# MAIN_PADCFG_CTRL_MAIN_PADCFG_CTRL_MMR_CFG0_000F0000h register map
Vendor: Texas Instruments
Peripheral module from a debugger description file (folder am62D).
Registers are 32-bit, access per field, reset 0x8214007 unless marked. A register's access mark holds for its fields unless they carry their own. Offsets are as the file gives them; lines under a group give offsets from that group; [hi:lo] are bit positions; {n}, {i} and the like mark numbered series; 'fields as' and 'values as' point back to an identical list; <NAME> marks a mode.

## main_padcfg_ctrl_mmr_cfg0 (part 1 of 3)
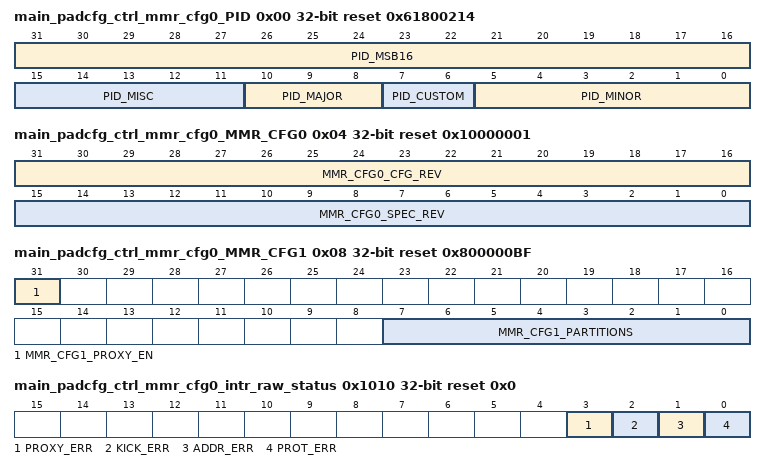
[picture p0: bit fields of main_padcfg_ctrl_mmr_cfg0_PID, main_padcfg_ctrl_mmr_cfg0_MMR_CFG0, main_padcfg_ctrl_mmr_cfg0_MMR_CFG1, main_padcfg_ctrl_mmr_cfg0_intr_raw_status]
0x00 main_padcfg_ctrl_mmr_cfg0_PID ro reset 0x61800214
  [31:16] PID_MSB16 — Reset Source: mod_g_rst_n
  [15:11] PID_MISC — Reset Source: mod_g_rst_n
  [10:8] PID_MAJOR — Reset Source: mod_g_rst_n
  [7:6] PID_CUSTOM — Reset Source: mod_g_rst_n
  [5:0] PID_MINOR — Reset Source: mod_g_rst_n
0x04 main_padcfg_ctrl_mmr_cfg0_MMR_CFG0 ro reset 0x10000001
  [31:16] MMR_CFG0_CFG_REV — Major configuration release Reset Source: mod_por_rst_n
  [15:0] MMR_CFG0_SPEC_REV — Minor spec-only revision. Doesn't change RTL release Reset Source: mod_por_rst_n
0x08 main_padcfg_ctrl_mmr_cfg0_MMR_CFG1 ro reset 0x800000BF
  [31] MMR_CFG1_PROXY_EN — Proxy addressing enabled Reset Source: mod_por_rst_n
  [7:0] MMR_CFG1_PARTITIONS — Indicates present partitions Reset Source: mod_por_rst_n
0x1008 main_padcfg_ctrl_mmr_cfg0_LOCK0_KICK0 rw reset 0x0
  [31:0] LOCK0_KICK0 — - KICK0 component Reset Source: mod_g_rst_n
0x100C main_padcfg_ctrl_mmr_cfg0_LOCK0_KICK1 rw reset 0x0
  [31:0] LOCK0_KICK1 — - KICK1 component Reset Source: mod_g_rst_n
0x1010 main_padcfg_ctrl_mmr_cfg0_intr_raw_status access not given reset 0x0
  [3] PROXY_ERR — Proxy0 access violation error. Raw status is read. Write a 1 to set the status. Writing a 0 has no effect. Reset Source: mod_g_rst_n (access R/W1TS)
  [2] KICK_ERR — Kick access violation error. Raw status is read. Write a 1 to set the status. Writing a 0 has no effect. Reset Source: mod_g_rst_n (access R/W1TS)
  [1] ADDR_ERR — Addressing violation error. Raw status is read. Write a 1 to set the status. Writing a 0 has no effect. Reset Source: mod_g_rst_n (access R/W1TS)
  [0] PROT_ERR — Protection violation error. Raw status is read. Write a 1 to set the status. Writing a 0 has no effect. Reset Source: mod_g_rst_n (access R/W1TS)
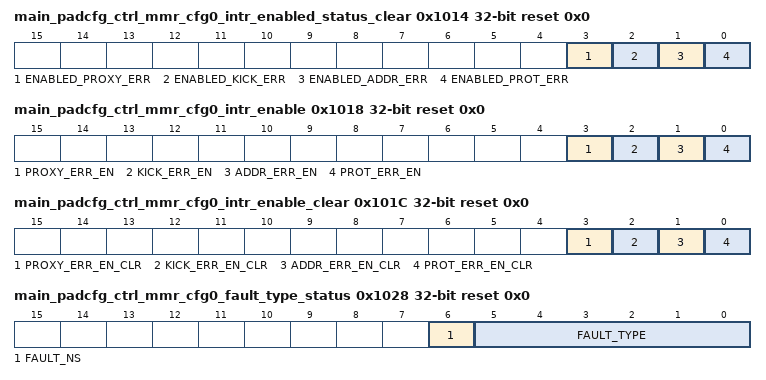
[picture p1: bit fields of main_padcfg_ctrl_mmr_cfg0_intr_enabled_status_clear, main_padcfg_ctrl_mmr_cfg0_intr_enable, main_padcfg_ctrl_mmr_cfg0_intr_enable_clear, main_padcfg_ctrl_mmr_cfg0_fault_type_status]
0x1014 main_padcfg_ctrl_mmr_cfg0_intr_enabled_status_clear access not given reset 0x0
  [3] ENABLED_PROXY_ERR — Proxy0 access violation error. Enabled status is read. Write a 1 to clear the status. Writing a 0 has no effect. Reset Source: mod_g_rst_n (access R/W1TC)
  [2] ENABLED_KICK_ERR — Kick access violation error. Enabled status is read. Write a 1 to clear the status. Writing a 0 has no effect. Reset Source: mod_g_rst_n (access R/W1TC)
  [1] ENABLED_ADDR_ERR — Addressing violation error. Enabled status is read. Write a 1 to clear the status. Writing a 0 has no effect. Reset Source: mod_g_rst_n (access R/W1TC)
  [0] ENABLED_PROT_ERR — Protection violation error. Enabled status is read. Write a 1 to clear the status. Writing a 0 has no effect. Reset Source: mod_g_rst_n (access R/W1TC)
0x1018 main_padcfg_ctrl_mmr_cfg0_intr_enable access not given reset 0x0
  [3] PROXY_ERR_EN — Proxy0 access violation error enable. Write a 1 to set the enable. Writing a 0 has no effect. Reset Source: mod_g_rst_n (access R/W1TS)
  [2] KICK_ERR_EN — Kick access violation error enable. Write a 1 to set the enable. Writing a 0 has no effect. Reset Source: mod_g_rst_n (access R/W1TS)
  [1] ADDR_ERR_EN — Addressing violation error enable. Write a 1 to set the enable. Writing a 0 has no effect. Reset Source: mod_g_rst_n (access R/W1TS)
  [0] PROT_ERR_EN — Protection violation error enable. Write a 1 to set the enable. Writing a 0 has no effect. Reset Source: mod_g_rst_n (access R/W1TS)
0x101C main_padcfg_ctrl_mmr_cfg0_intr_enable_clear access not given reset 0x0
  [3] PROXY_ERR_EN_CLR — Proxy0 access violation error enable clear. Write a 1 to clear the enable. Writing a 0 has no effect. Reset Source: mod_g_rst_n (access R/W1TC)
  [2] KICK_ERR_EN_CLR — Kick access violation error enable clear. Write a 1 to clear the enable. Writing a 0 has no effect. Reset Source: mod_g_rst_n (access R/W1TC)
  [1] ADDR_ERR_EN_CLR — Addressing violation error enable clear. Write a 1 to clear the enable. Writing a 0 has no effect. Reset Source: mod_g_rst_n (access R/W1TC)
  [0] PROT_ERR_EN_CLR — Protection violation error enable clear. Write a 1 to clear the enable. Writing a 0 has no effect. Reset Source: mod_g_rst_n (access R/W1TC)
0x1020 main_padcfg_ctrl_mmr_cfg0_eoi rw reset 0x0
  [7:0] EOI_VECTOR — EOI vector value. Write this with interrupt distribution value in the chip. Reset Source: mod_g_rst_n
0x1024 main_padcfg_ctrl_mmr_cfg0_fault_address ro reset 0x0
  [31:0] FAULT_ADDR — Fault Address. Reset Source: mod_g_rst_n
0x1028 main_padcfg_ctrl_mmr_cfg0_fault_type_status ro reset 0x0
  [6] FAULT_NS — Non-secure access. Reset Source: mod_g_rst_n
  [5:0] FAULT_TYPE — Fault Type 10_0000 = Supervisor read fault - priv = 1 dir = 1 dtype != 1 01_0000 = Supervisor write fault - priv = 1 dir = 0 00_1000 = Supervisor execute fault - priv = 1 dir = 1 dtype = 1 00_0100 = User read fault - priv = 0 dir = 1 dtype = 1 00_0010 = User write fault - priv = 0 dir = 0 00_0001 = User execute fault - priv = 0 dir = 1 dtype = 1 00_0000 = No fault Reset Source: mod_g_rst_n
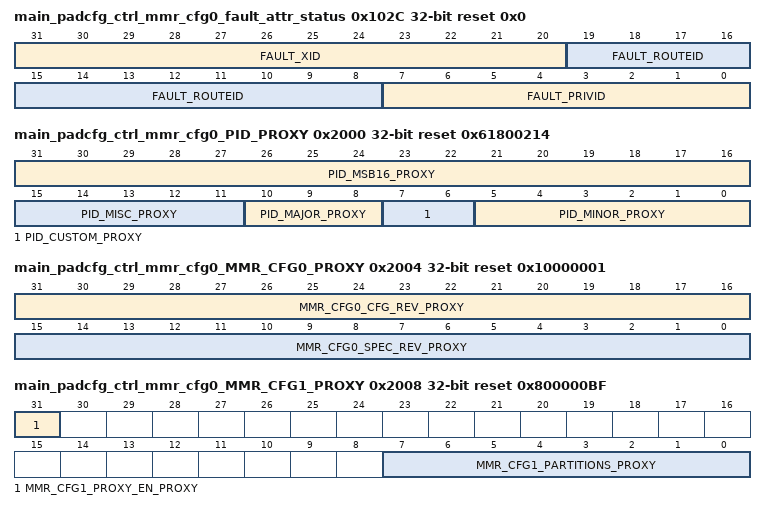
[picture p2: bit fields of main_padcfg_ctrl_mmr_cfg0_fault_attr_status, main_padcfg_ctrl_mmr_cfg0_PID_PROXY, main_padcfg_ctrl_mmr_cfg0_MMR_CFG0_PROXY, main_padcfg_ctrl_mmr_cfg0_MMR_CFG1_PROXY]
0x102C main_padcfg_ctrl_mmr_cfg0_fault_attr_status ro reset 0x0
  [31:20] FAULT_XID — XID. Reset Source: mod_g_rst_n
  [19:8] FAULT_ROUTEID — Route ID. Reset Source: mod_g_rst_n
  [7:0] FAULT_PRIVID — Privilege ID. Reset Source: mod_g_rst_n
0x1030 main_padcfg_ctrl_mmr_cfg0_fault_clear wo reset 0x0
  [0] FAULT_CLR — Fault clear. Writing a 1 clears the current fault. Writing a 0 has no effect. Reset Source: mod_g_rst_n
0x1100 main_padcfg_ctrl_mmr_cfg0_CLAIMREG_P0_R0_READONLY ro reset 0x0
  [31:0] CLAIMREG_P0_R0_READONLY — Claim bits for Partition 0 Reset Source: mod_g_rst_n
0x2000 main_padcfg_ctrl_mmr_cfg0_PID_PROXY ro reset 0x61800214
  [31:16] PID_MSB16_PROXY — Reset Source: mod_g_rst_n
  [15:11] PID_MISC_PROXY — Reset Source: mod_g_rst_n
  [10:8] PID_MAJOR_PROXY — Reset Source: mod_g_rst_n
  [7:6] PID_CUSTOM_PROXY — Reset Source: mod_g_rst_n
  [5:0] PID_MINOR_PROXY — Reset Source: mod_g_rst_n
0x2004 main_padcfg_ctrl_mmr_cfg0_MMR_CFG0_PROXY ro reset 0x10000001
  [31:16] MMR_CFG0_CFG_REV_PROXY — Major configuration release Reset Source: mod_por_rst_n
  [15:0] MMR_CFG0_SPEC_REV_PROXY — Minor spec-only revision. Doesn't change RTL release Reset Source: mod_por_rst_n
0x2008 main_padcfg_ctrl_mmr_cfg0_MMR_CFG1_PROXY ro reset 0x800000BF
  [31] MMR_CFG1_PROXY_EN_PROXY — Proxy addressing enabled Reset Source: mod_por_rst_n
  [7:0] MMR_CFG1_PARTITIONS_PROXY — Indicates present partitions Reset Source: mod_por_rst_n
0x3008 main_padcfg_ctrl_mmr_cfg0_LOCK0_KICK0_PROXY rw reset 0x0
  [31:0] LOCK0_KICK0_PROXY — - KICK0 component Reset Source: mod_g_rst_n
0x300C main_padcfg_ctrl_mmr_cfg0_LOCK0_KICK1_PROXY rw reset 0x0
  [31:0] LOCK0_KICK1_PROXY — - KICK1 component Reset Source: mod_g_rst_n
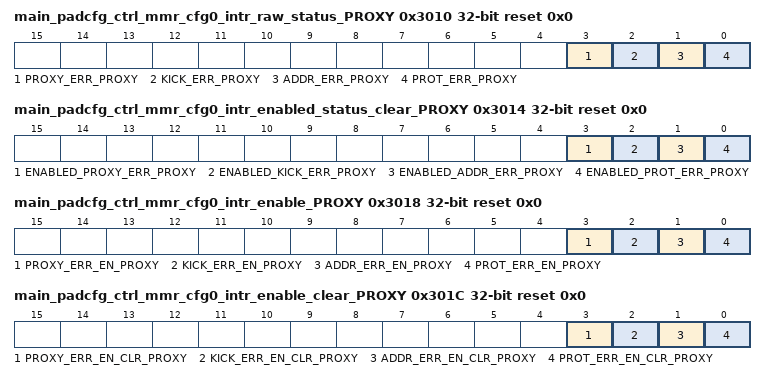
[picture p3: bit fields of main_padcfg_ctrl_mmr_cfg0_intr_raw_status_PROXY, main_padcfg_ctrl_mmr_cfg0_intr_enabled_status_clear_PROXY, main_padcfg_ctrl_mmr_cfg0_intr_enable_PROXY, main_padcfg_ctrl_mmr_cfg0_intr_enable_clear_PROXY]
0x3010 main_padcfg_ctrl_mmr_cfg0_intr_raw_status_PROXY access not given reset 0x0
  [3] PROXY_ERR_PROXY — Proxy0 access violation error. Raw status is read. Write a 1 to set the status. Writing a 0 has no effect. Reset Source: mod_g_rst_n (access R/W1TS)
  [2] KICK_ERR_PROXY — Kick access violation error. Raw status is read. Write a 1 to set the status. Writing a 0 has no effect. Reset Source: mod_g_rst_n (access R/W1TS)
  [1] ADDR_ERR_PROXY — Addressing violation error. Raw status is read. Write a 1 to set the status. Writing a 0 has no effect. Reset Source: mod_g_rst_n (access R/W1TS)
  [0] PROT_ERR_PROXY — Protection violation error. Raw status is read. Write a 1 to set the status. Writing a 0 has no effect. Reset Source: mod_g_rst_n (access R/W1TS)
0x3014 main_padcfg_ctrl_mmr_cfg0_intr_enabled_status_clear_PROXY access not given reset 0x0
  [3] ENABLED_PROXY_ERR_PROXY — Proxy0 access violation error. Enabled status is read. Write a 1 to clear the status. Writing a 0 has no effect. Reset Source: mod_g_rst_n (access R/W1TC)
  [2] ENABLED_KICK_ERR_PROXY — Kick access violation error. Enabled status is read. Write a 1 to clear the status. Writing a 0 has no effect. Reset Source: mod_g_rst_n (access R/W1TC)
  [1] ENABLED_ADDR_ERR_PROXY — Addressing violation error. Enabled status is read. Write a 1 to clear the status. Writing a 0 has no effect. Reset Source: mod_g_rst_n (access R/W1TC)
  [0] ENABLED_PROT_ERR_PROXY — Protection violation error. Enabled status is read. Write a 1 to clear the status. Writing a 0 has no effect. Reset Source: mod_g_rst_n (access R/W1TC)
0x3018 main_padcfg_ctrl_mmr_cfg0_intr_enable_PROXY access not given reset 0x0
  [3] PROXY_ERR_EN_PROXY — Proxy0 access violation error enable. Write a 1 to set the enable. Writing a 0 has no effect. Reset Source: mod_g_rst_n (access R/W1TS)
  [2] KICK_ERR_EN_PROXY — Kick access violation error enable. Write a 1 to set the enable. Writing a 0 has no effect. Reset Source: mod_g_rst_n (access R/W1TS)
  [1] ADDR_ERR_EN_PROXY — Addressing violation error enable. Write a 1 to set the enable. Writing a 0 has no effect. Reset Source: mod_g_rst_n (access R/W1TS)
  [0] PROT_ERR_EN_PROXY — Protection violation error enable. Write a 1 to set the enable. Writing a 0 has no effect. Reset Source: mod_g_rst_n (access R/W1TS)
0x301C main_padcfg_ctrl_mmr_cfg0_intr_enable_clear_PROXY access not given reset 0x0
  [3] PROXY_ERR_EN_CLR_PROXY — Proxy0 access violation error enable clear. Write a 1 to clear the enable. Writing a 0 has no effect. Reset Source: mod_g_rst_n (access R/W1TC)
  [2] KICK_ERR_EN_CLR_PROXY — Kick access violation error enable clear. Write a 1 to clear the enable. Writing a 0 has no effect. Reset Source: mod_g_rst_n (access R/W1TC)
  [1] ADDR_ERR_EN_CLR_PROXY — Addressing violation error enable clear. Write a 1 to clear the enable. Writing a 0 has no effect. Reset Source: mod_g_rst_n (access R/W1TC)
  [0] PROT_ERR_EN_CLR_PROXY — Protection violation error enable clear. Write a 1 to clear the enable. Writing a 0 has no effect. Reset Source: mod_g_rst_n (access R/W1TC)
0x3020 main_padcfg_ctrl_mmr_cfg0_eoi_PROXY rw reset 0x0
  [7:0] EOI_VECTOR_PROXY — EOI vector value. Write this with interrupt distribution value in the chip. Reset Source: mod_g_rst_n
0x3024 main_padcfg_ctrl_mmr_cfg0_fault_address_PROXY ro reset 0x0
  [31:0] FAULT_ADDR_PROXY — Fault Address. Reset Source: mod_g_rst_n
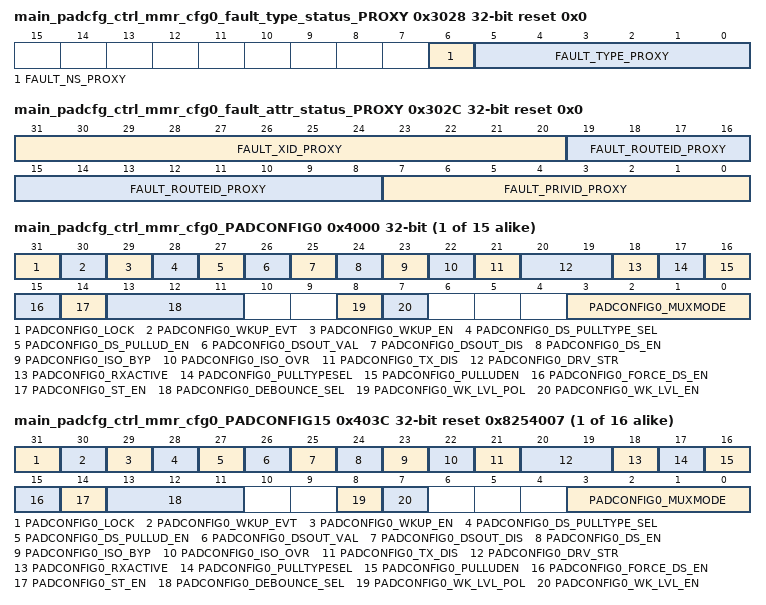
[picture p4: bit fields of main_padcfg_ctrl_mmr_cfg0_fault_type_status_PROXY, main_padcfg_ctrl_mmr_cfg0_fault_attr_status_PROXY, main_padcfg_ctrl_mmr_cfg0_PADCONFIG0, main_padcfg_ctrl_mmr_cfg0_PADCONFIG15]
0x3028 main_padcfg_ctrl_mmr_cfg0_fault_type_status_PROXY ro reset 0x0
  [6] FAULT_NS_PROXY — Non-secure access. Reset Source: mod_g_rst_n
  [5:0] FAULT_TYPE_PROXY — Fault Type 10_0000 = Supervisor read fault - priv = 1 dir = 1 dtype != 1 01_0000 = Supervisor write fault - priv = 1 dir = 0 00_1000 = Supervisor execute fault - priv = 1 dir = 1 dtype = 1 00_0100 = User read fault - priv = 0 dir = 1 dtype = 1 00_0010 = User write fault - priv = 0 dir = 0 00_0001 = User execute fault - priv = 0 dir = 1 dtype = 1 00_0000 = No fault Reset Source: mod_g_rst_n
0x302C main_padcfg_ctrl_mmr_cfg0_fault_attr_status_PROXY ro reset 0x0
  [31:20] FAULT_XID_PROXY — XID. Reset Source: mod_g_rst_n
  [19:8] FAULT_ROUTEID_PROXY — Route ID. Reset Source: mod_g_rst_n
  [7:0] FAULT_PRIVID_PROXY — Privilege ID. Reset Source: mod_g_rst_n
0x3030 main_padcfg_ctrl_mmr_cfg0_fault_clear_PROXY wo reset 0x0
  [0] FAULT_CLR_PROXY — Fault clear. Writing a 1 clears the current fault. Writing a 0 has no effect. Reset Source: mod_g_rst_n
0x3100 main_padcfg_ctrl_mmr_cfg0_CLAIMREG_P0_R0 rw reset 0x0
  [31:0] CLAIMREG_P0_R0 — Claim bits for Partition 0 Reset Source: mod_g_rst_n
{0x4000+4i} main_padcfg_ctrl_mmr_cfg0_PADCONFIG{i} (i=0..14)
  [31] PADCONFIG{i}_LOCK rw — Lock 0 - Padconfig register is unlocked 1 - Padconfig register is locked from further writes Reset Source: mod_por_rst_n
  [30] PADCONFIG{i}_WKUP_EVT ro — Wakeup event status 0 - No wake event on pin 1 - Wake event occurred on pin Reset Source: mod_por_rst_n
  [29] PADCONFIG{i}_WKUP_EN rw — Wakeup enable 0 - Wakeup operation disabled 1 - Wakeup operation enabled Reset Source: mod_por_rst_n
  [28] PADCONFIG{i}_DS_PULLTYPE_SEL rw — Deep Sleep pull-up/down selection 0 - Offmode pulldown selected 1 - Offmode pullup selected Reset Source: mod_por_rst_n
  [27] PADCONFIG{i}_DS_PULLUD_EN rw — Deep Sleep pull-up/down enable (active low) 0 - Pullup / pulldown is enabled 1 - Pullup / pulldown is disabled Reset Source: mod_por_rst_n
  [26] PADCONFIG{i}_DSOUT_VAL rw — Deep Sleep output value 0 - Output value is 0 1 - Output value is 1 Reset Source: mod_por_rst_n
  [25] PADCONFIG{i}_DSOUT_DIS rw — Deep Sleep output disable 0 - Output enabled 1 - Output disabled Reset Source: mod_por_rst_n
  [24] PADCONFIG{i}_DS_EN rw — Deep Sleep override control 0 - IO keeps its previous state when Deep Sleep mode is active 1 - IO state is forced to OFF mode value when Deep Sleep mode is active Reset Source: mod_por_rst_n
  [23] PADCONFIG{i}_ISO_BYP rw — Isolation Bypass0 - IO isolation is preserved1 - IO isolation is bypassed Reset Source: mod_por_rst_n
  [22] PADCONFIG{i}_ISO_OVR rw — Isolation Override0 - IO isolation is preserved1 - IO isolation is overridden Reset Source: mod_por_rst_n
  [21] PADCONFIG{i}_TX_DIS rw — Driver Disable0 - Driver is enabled1 - Driver is disabled Reset Source: mod_por_rst_n
  [20:19] PADCONFIG{i}_DRV_STR rw — Drive Strength Control . Selects the drive strength value for LVCMOS pins. (Does not apply to other pin types) Reset Source: mod_por_rst_n
  [18] PADCONFIG{i}_RXACTIVE rw — Input enable for the Pad0 - Receiver disabled1 - Receiver enabled Reset Source: mod_por_rst_n
  [17] PADCONFIG{i}_PULLTYPESEL rw — Pad Pullup / Pulldown type selection0 - Pulldown selected1 - Pullup selected Reset Source: mod_por_rst_n
  [16] PADCONFIG{i}_PULLUDEN rw — Pad Pullup / Pulldown enable. This is an active low signal.0 - Pullup / Pulldown enabled1 - Pullup / Pulldown disabled Reset Source: mod_por_rst_n
  [15] PADCONFIG{i}_FORCE_DS_EN rw — Enable pad Deep Sleep controls by overriding WKUP DM gating0 - Deep Sleep pad controls are gated by the WKUP DM1 - Activate Deep Sleep pad controls (override WKUP DM gating logic) Reset Source: mod_por_rst_n
  [14] PADCONFIG{i}_ST_EN rw — Receiver Schmitt Trigger enable 0 - Schmitt trigger input disabled 1 - Schmitt trigger input enabled Reset Source: mod_por_rst_n
  [13:11] PADCONFIG{i}_DEBOUNCE_SEL rw — Selects the debouce period for the pad. Reset Source: mod_por_rst_n
  [8] PADCONFIG{i}_WK_LVL_POL rw — Level Sensitive Wakeup PolarityThis bit is not relevant unless wk_lvl_en is set to 1'b1.0 - Low. A low (0) value on the pin causes a wakeup1 - High. A high (1) value on the pin causes a wakeup Reset Source: mod_por_rst_n
  [7] PADCONFIG{i}_WK_LVL_EN rw — Level Sensitive Wakeup Enable0 - Disabled. Wakeup is triggered by change of the pin input value1 - Enabled. Wakeup is triggered when the pin matches the value specified by wk_lvl_pol. The chosen polarity must be maintained. (e.g. until wakeup completion is confirmed) Reset Source: mod_por_rst_n
  [3:0] PADCONFIG{i}_MUXMODE rw — Pad functional signal mux selectionField values (others are reserved):4'b0000 - Mux Mode 04'b0001 - Mux Mode 14'b0010 - Mux Mode 24'b0011 - Mux Mode 34'b0100 - Mux Mode 44'b0101 - Mux Mode 54'b0110 - Mux Mode 64'b0111 - Mux Mode 74'b1000 - Mux Mode 84'b1001 - Mux Mode 94'b1010 - Mux Mode 104'b1011 - Mux Mode 114'b1100 - Mux Mode 124'b1101 - Mux Mode 134'b1110 - Mux Mode 144'b1111 - Mux Mode 15 Reset Source: mod_por_rst_n
{0x4000+4i} main_padcfg_ctrl_mmr_cfg0_PADCONFIG{i} reset 0x8254007 (i=15..30)
  fields as main_padcfg_ctrl_mmr_cfg0_PADCONFIG0
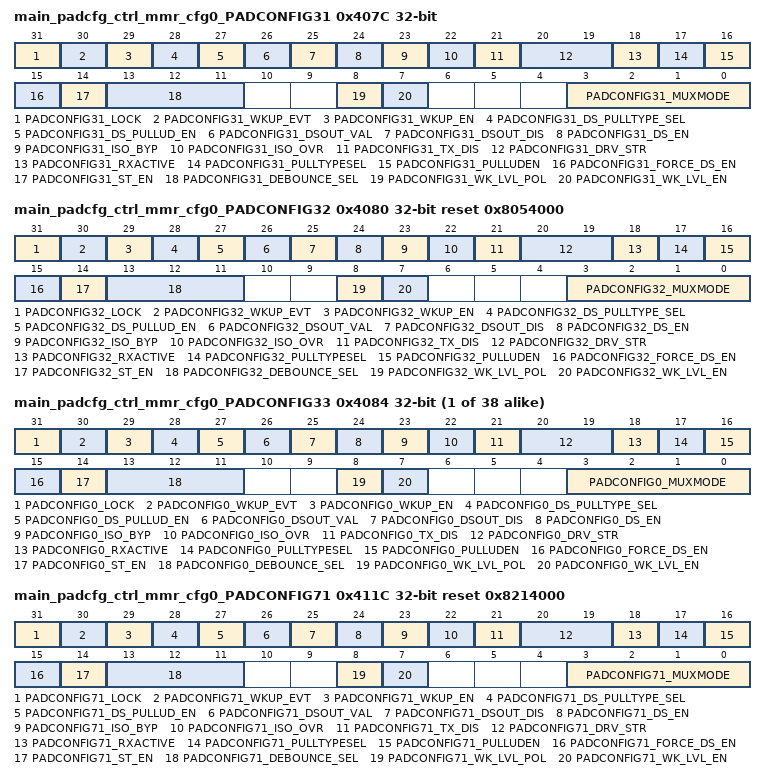
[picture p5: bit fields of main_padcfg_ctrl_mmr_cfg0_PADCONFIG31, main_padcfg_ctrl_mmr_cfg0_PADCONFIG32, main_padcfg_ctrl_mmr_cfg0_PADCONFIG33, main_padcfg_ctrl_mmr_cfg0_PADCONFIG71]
0x407C main_padcfg_ctrl_mmr_cfg0_PADCONFIG31
  [31] PADCONFIG31_LOCK rw — Lock 0 - Padconfig register is unlocked 1 - Padconfig register is locked from further writes Reset Source: mod_por_rst_n
  [30] PADCONFIG31_WKUP_EVT ro — Wakeup event status 0 - No wake event on pin 1 - Wake event occurred on pin Reset Source: mod_por_rst_n
  [29] PADCONFIG31_WKUP_EN rw — Wakeup enable 0 - Wakeup operation disabled 1 - Wakeup operation enabled Reset Source: mod_por_rst_n
  [28] PADCONFIG31_DS_PULLTYPE_SEL rw — Deep Sleep pull-up/down selection 0 - Offmode pulldown selected 1 - Offmode pullup selected Reset Source: mod_por_rst_n
  [27] PADCONFIG31_DS_PULLUD_EN rw — Deep Sleep pull-up/down enable (active low) 0 - Pullup / pulldown is enabled 1 - Pullup / pulldown is disabled Reset Source: mod_por_rst_n
  [26] PADCONFIG31_DSOUT_VAL rw — Deep Sleep output value 0 - Output value is 0 1 - Output value is 1 Reset Source: mod_por_rst_n
  [25] PADCONFIG31_DSOUT_DIS rw — Deep Sleep output disable 0 - Output enabled 1 - Output disabled Reset Source: mod_por_rst_n
  [24] PADCONFIG31_DS_EN rw — Deep Sleep override control 0 - IO keeps its previous state when Deep Sleep mode is active 1 - IO state is forced to OFF mode value when Deep Sleep mode is active Reset Source: mod_por_rst_n
  [23] PADCONFIG31_ISO_BYP rw — Isolation Bypass0 - IO isolation is preserved1 - IO isolation is bypassed Reset Source: mod_por_rst_n
  [22] PADCONFIG31_ISO_OVR rw — Isolation Override0 - IO isolation is preserved1 - IO isolation is overridden Reset Source: mod_por_rst_n
  [21] PADCONFIG31_TX_DIS rw — Driver Disable0 - Driver is enabled1 - Driver is disabled Reset Source: mod_por_rst_n
  [20:19] PADCONFIG31_DRV_STR rw — Drive Strength Control . Selects the drive strength value for LVCMOS pins. (Does not apply to other pin types) Reset Source: mod_por_rst_n
  [18] PADCONFIG31_RXACTIVE rw — Input enable for the Pad0 - Receiver disabled1 - Receiver enabled Reset Source: mod_por_rst_n
  [17] PADCONFIG31_PULLTYPESEL rw — Pad Pullup / Pulldown type selection0 - Pulldown selected1 - Pullup selected Reset Source: mod_por_rst_n
  [16] PADCONFIG31_PULLUDEN rw — Pad Pullup / Pulldown enable. This is an active low signal.0 - Pullup / Pulldown enabled1 - Pullup / Pulldown disabled Reset Source: mod_por_rst_n
  [15] PADCONFIG31_FORCE_DS_EN rw — Enable pad Deep Sleep controls by overriding WKUP DM gating0 - Deep Sleep pad controls are gated by the WKUP DM1 - Activate Deep Sleep pad controls (override WKUP DM gating logic) Reset Source: mod_por_rst_n
  [14] PADCONFIG31_ST_EN rw — Receiver Schmitt Trigger enable 0 - Schmitt trigger input disabled 1 - Schmitt trigger input enabled Reset Source: mod_por_rst_n
  [13:11] PADCONFIG31_DEBOUNCE_SEL rw — Selects the debouce period for the pad. Reset Source: mod_por_rst_n
  [8] PADCONFIG31_WK_LVL_POL rw — Level Sensitive Wakeup PolarityThis bit is not relevant unless wk_lvl_en is set to 1'b1.0 - Low. A low (0) value on the pin causes a wakeup1 - High. A high (1) value on the pin causes a wakeup Reset Source: mod_por_rst_n
  [7] PADCONFIG31_WK_LVL_EN rw — Level Sensitive Wakeup Enable0 - Disabled. Wakeup is triggered by change of the pin input value1 - Enabled. Wakeup is triggered when the pin matches the value specified by wk_lvl_pol. The chosen polarity must be maintained. (e.g. until wakeup completion is confirmed) Reset Source: mod_por_rst_n
  [3:0] PADCONFIG31_MUXMODE rw — Pad functional signal mux selectionField values (others are reserved):4'b0000 - Mux Mode 04'b0001 - Mux Mode 14'b0010 - Mux Mode 24'b0011 - Mux Mode 34'b0100 - Mux Mode 44'b0101 - Mux Mode 54'b0110 - Mux Mode 64'b0111 - Mux Mode 74'b1000 - Mux Mode 84'b1001 - Mux Mode 94'b1010 - Mux Mode 104'b1011 - Mux Mode 114'b1100 - Mux Mode 124'b1101 - Mux Mode 134'b1110 - Mux Mode 144'b1111 - Mux Mode 15 Reset Source: mod_por_rst_n
0x4080 main_padcfg_ctrl_mmr_cfg0_PADCONFIG32 reset 0x8054000
  [31] PADCONFIG32_LOCK rw — Lock 0 - Padconfig register is unlocked 1 - Padconfig register is locked from further writes Reset Source: mod_por_rst_n
  [30] PADCONFIG32_WKUP_EVT ro — Wakeup event status 0 - No wake event on pin 1 - Wake event occurred on pin Reset Source: mod_por_rst_n
  [29] PADCONFIG32_WKUP_EN rw — Wakeup enable 0 - Wakeup operation disabled 1 - Wakeup operation enabled Reset Source: mod_por_rst_n
  [28] PADCONFIG32_DS_PULLTYPE_SEL rw — Deep Sleep pull-up/down selection 0 - Offmode pulldown selected 1 - Offmode pullup selected Reset Source: mod_por_rst_n
  [27] PADCONFIG32_DS_PULLUD_EN rw — Deep Sleep pull-up/down enable (active low) 0 - Pullup / pulldown is enabled 1 - Pullup / pulldown is disabled Reset Source: mod_por_rst_n
  [26] PADCONFIG32_DSOUT_VAL rw — Deep Sleep output value 0 - Output value is 0 1 - Output value is 1 Reset Source: mod_por_rst_n
  [25] PADCONFIG32_DSOUT_DIS rw — Deep Sleep output disable 0 - Output enabled 1 - Output disabled Reset Source: mod_por_rst_n
  [24] PADCONFIG32_DS_EN rw — Deep Sleep override control 0 - IO keeps its previous state when Deep Sleep mode is active 1 - IO state is forced to OFF mode value when Deep Sleep mode is active Reset Source: mod_por_rst_n
  [23] PADCONFIG32_ISO_BYP rw — Isolation Bypass0 - IO isolation is preserved1 - IO isolation is bypassed Reset Source: mod_por_rst_n
  [22] PADCONFIG32_ISO_OVR rw — Isolation Override0 - IO isolation is preserved1 - IO isolation is overridden Reset Source: mod_por_rst_n
  [21] PADCONFIG32_TX_DIS rw — Driver Disable0 - Driver is enabled1 - Driver is disabled Reset Source: mod_por_rst_n
  [20:19] PADCONFIG32_DRV_STR rw — Drive Strength Control . Selects the drive strength value for LVCMOS pins. (Does not apply to other pin types) Reset Source: mod_por_rst_n
  [18] PADCONFIG32_RXACTIVE rw — Input enable for the Pad0 - Receiver disabled1 - Receiver enabled Reset Source: mod_por_rst_n
  [17] PADCONFIG32_PULLTYPESEL rw — Pad Pullup / Pulldown type selection0 - Pulldown selected1 - Pullup selected Reset Source: mod_por_rst_n
  [16] PADCONFIG32_PULLUDEN rw — Pad Pullup / Pulldown enable. This is an active low signal.0 - Pullup / Pulldown enabled1 - Pullup / Pulldown disabled Reset Source: mod_por_rst_n
  [15] PADCONFIG32_FORCE_DS_EN rw — Enable pad Deep Sleep controls by overriding WKUP DM gating0 - Deep Sleep pad controls are gated by the WKUP DM1 - Activate Deep Sleep pad controls (override WKUP DM gating logic) Reset Source: mod_por_rst_n
  [14] PADCONFIG32_ST_EN rw — Receiver Schmitt Trigger enable 0 - Schmitt trigger input disabled 1 - Schmitt trigger input enabled Reset Source: mod_por_rst_n
  [13:11] PADCONFIG32_DEBOUNCE_SEL rw — Selects the debouce period for the pad. Reset Source: mod_por_rst_n
  [8] PADCONFIG32_WK_LVL_POL rw — Level Sensitive Wakeup PolarityThis bit is not relevant unless wk_lvl_en is set to 1'b1.0 - Low. A low (0) value on the pin causes a wakeup1 - High. A high (1) value on the pin causes a wakeup Reset Source: mod_por_rst_n
  [7] PADCONFIG32_WK_LVL_EN rw — Level Sensitive Wakeup Enable0 - Disabled. Wakeup is triggered by change of the pin input value1 - Enabled. Wakeup is triggered when the pin matches the value specified by wk_lvl_pol. The chosen polarity must be maintained. (e.g. until wakeup completion is confirmed) Reset Source: mod_por_rst_n
  [3:0] PADCONFIG32_MUXMODE rw — Pad functional signal mux selectionField values (others are reserved):4'b0000 - Mux Mode 04'b0001 - Mux Mode 14'b0010 - Mux Mode 24'b0011 - Mux Mode 34'b0100 - Mux Mode 44'b0101 - Mux Mode 54'b0110 - Mux Mode 64'b0111 - Mux Mode 74'b1000 - Mux Mode 84'b1001 - Mux Mode 94'b1010 - Mux Mode 104'b1011 - Mux Mode 114'b1100 - Mux Mode 124'b1101 - Mux Mode 134'b1110 - Mux Mode 144'b1111 - Mux Mode 15 Reset Source: mod_por_rst_n
{0x4000+4i} main_padcfg_ctrl_mmr_cfg0_PADCONFIG{i} (i=33..70)
  fields as main_padcfg_ctrl_mmr_cfg0_PADCONFIG0
0x411C main_padcfg_ctrl_mmr_cfg0_PADCONFIG71 reset 0x8214000
  [31] PADCONFIG71_LOCK rw — Lock 0 - Padconfig register is unlocked 1 - Padconfig register is locked from further writes Reset Source: mod_por_rst_n
  [30] PADCONFIG71_WKUP_EVT ro — Wakeup event status 0 - No wake event on pin 1 - Wake event occurred on pin Reset Source: mod_por_rst_n
  [29] PADCONFIG71_WKUP_EN rw — Wakeup enable 0 - Wakeup operation disabled 1 - Wakeup operation enabled Reset Source: mod_por_rst_n
  [28] PADCONFIG71_DS_PULLTYPE_SEL rw — Deep Sleep pull-up/down selection 0 - Offmode pulldown selected 1 - Offmode pullup selected Reset Source: mod_por_rst_n
  [27] PADCONFIG71_DS_PULLUD_EN rw — Deep Sleep pull-up/down enable (active low) 0 - Pullup / pulldown is enabled 1 - Pullup / pulldown is disabled Reset Source: mod_por_rst_n
  [26] PADCONFIG71_DSOUT_VAL rw — Deep Sleep output value 0 - Output value is 0 1 - Output value is 1 Reset Source: mod_por_rst_n
  [25] PADCONFIG71_DSOUT_DIS rw — Deep Sleep output disable 0 - Output enabled 1 - Output disabled Reset Source: mod_por_rst_n
  [24] PADCONFIG71_DS_EN rw — Deep Sleep override control 0 - IO keeps its previous state when Deep Sleep mode is active 1 - IO state is forced to OFF mode value when Deep Sleep mode is active Reset Source: mod_por_rst_n
  [23] PADCONFIG71_ISO_BYP rw — Isolation Bypass0 - IO isolation is preserved1 - IO isolation is bypassed Reset Source: mod_por_rst_n
  [22] PADCONFIG71_ISO_OVR rw — Isolation Override0 - IO isolation is preserved1 - IO isolation is overridden Reset Source: mod_por_rst_n
  [21] PADCONFIG71_TX_DIS rw — Driver Disable0 - Driver is enabled1 - Driver is disabled Reset Source: mod_por_rst_n
  [20:19] PADCONFIG71_DRV_STR rw — Drive Strength Control . Selects the drive strength value for LVCMOS pins. (Does not apply to other pin types) Reset Source: mod_por_rst_n
  [18] PADCONFIG71_RXACTIVE rw — Input enable for the Pad0 - Receiver disabled1 - Receiver enabled Reset Source: mod_por_rst_n
  [17] PADCONFIG71_PULLTYPESEL rw — Pad Pullup / Pulldown type selection0 - Pulldown selected1 - Pullup selected Reset Source: mod_por_rst_n
  [16] PADCONFIG71_PULLUDEN rw — Pad Pullup / Pulldown enable. This is an active low signal.0 - Pullup / Pulldown enabled1 - Pullup / Pulldown disabled Reset Source: mod_por_rst_n
  [15] PADCONFIG71_FORCE_DS_EN rw — Enable pad Deep Sleep controls by overriding WKUP DM gating0 - Deep Sleep pad controls are gated by the WKUP DM1 - Activate Deep Sleep pad controls (override WKUP DM gating logic) Reset Source: mod_por_rst_n
  [14] PADCONFIG71_ST_EN rw — Receiver Schmitt Trigger enable 0 - Schmitt trigger input disabled 1 - Schmitt trigger input enabled Reset Source: mod_por_rst_n
  [13:11] PADCONFIG71_DEBOUNCE_SEL rw — Selects the debouce period for the pad. Reset Source: mod_por_rst_n
  [8] PADCONFIG71_WK_LVL_POL rw — Level Sensitive Wakeup PolarityThis bit is not relevant unless wk_lvl_en is set to 1'b1.0 - Low. A low (0) value on the pin causes a wakeup1 - High. A high (1) value on the pin causes a wakeup Reset Source: mod_por_rst_n
  [7] PADCONFIG71_WK_LVL_EN rw — Level Sensitive Wakeup Enable0 - Disabled. Wakeup is triggered by change of the pin input value1 - Enabled. Wakeup is triggered when the pin matches the value specified by wk_lvl_pol. The chosen polarity must be maintained. (e.g. until wakeup completion is confirmed) Reset Source: mod_por_rst_n
  [3:0] PADCONFIG71_MUXMODE rw — Pad functional signal mux selectionField values (others are reserved):4'b0000 - Mux Mode 04'b0001 - Mux Mode 14'b0010 - Mux Mode 24'b0011 - Mux Mode 34'b0100 - Mux Mode 44'b0101 - Mux Mode 54'b0110 - Mux Mode 64'b0111 - Mux Mode 74'b1000 - Mux Mode 84'b1001 - Mux Mode 94'b1010 - Mux Mode 104'b1011 - Mux Mode 114'b1100 - Mux Mode 124'b1101 - Mux Mode 134'b1110 - Mux Mode 144'b1111 - Mux Mode 15 Reset Source: mod_por_rst_n
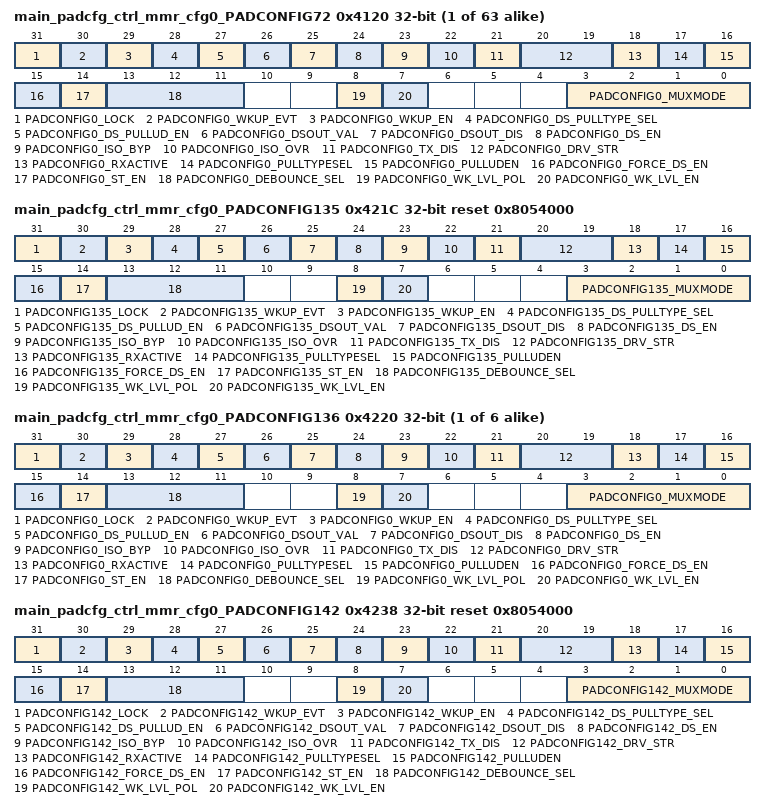
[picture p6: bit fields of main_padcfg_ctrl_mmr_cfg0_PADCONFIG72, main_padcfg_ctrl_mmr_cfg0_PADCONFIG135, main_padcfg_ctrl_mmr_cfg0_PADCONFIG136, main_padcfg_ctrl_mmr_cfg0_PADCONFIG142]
{0x4000+4i} main_padcfg_ctrl_mmr_cfg0_PADCONFIG{i} (i=72..134)
  fields as main_padcfg_ctrl_mmr_cfg0_PADCONFIG0
0x421C main_padcfg_ctrl_mmr_cfg0_PADCONFIG135 reset 0x8054000
  [31] PADCONFIG135_LOCK rw — Lock 0 - Padconfig register is unlocked 1 - Padconfig register is locked from further writes Reset Source: mod_por_rst_n
  [30] PADCONFIG135_WKUP_EVT ro — Wakeup event status 0 - No wake event on pin 1 - Wake event occurred on pin Reset Source: mod_por_rst_n
  [29] PADCONFIG135_WKUP_EN rw — Wakeup enable 0 - Wakeup operation disabled 1 - Wakeup operation enabled Reset Source: mod_por_rst_n
  [28] PADCONFIG135_DS_PULLTYPE_SEL rw — Deep Sleep pull-up/down selection 0 - Offmode pulldown selected 1 - Offmode pullup selected Reset Source: mod_por_rst_n
  [27] PADCONFIG135_DS_PULLUD_EN rw — Deep Sleep pull-up/down enable (active low) 0 - Pullup / pulldown is enabled 1 - Pullup / pulldown is disabled Reset Source: mod_por_rst_n
  [26] PADCONFIG135_DSOUT_VAL rw — Deep Sleep output value 0 - Output value is 0 1 - Output value is 1 Reset Source: mod_por_rst_n
  [25] PADCONFIG135_DSOUT_DIS rw — Deep Sleep output disable 0 - Output enabled 1 - Output disabled Reset Source: mod_por_rst_n
  [24] PADCONFIG135_DS_EN rw — Deep Sleep override control 0 - IO keeps its previous state when Deep Sleep mode is active 1 - IO state is forced to OFF mode value when Deep Sleep mode is active Reset Source: mod_por_rst_n
  [23] PADCONFIG135_ISO_BYP rw — Isolation Bypass0 - IO isolation is preserved1 - IO isolation is bypassed Reset Source: mod_por_rst_n
  [22] PADCONFIG135_ISO_OVR rw — Isolation Override0 - IO isolation is preserved1 - IO isolation is overridden Reset Source: mod_por_rst_n
  [21] PADCONFIG135_TX_DIS rw — Driver Disable0 - Driver is enabled1 - Driver is disabled Reset Source: mod_por_rst_n
  [20:19] PADCONFIG135_DRV_STR rw — Drive Strength Control . Selects the drive strength value for LVCMOS pins. (Does not apply to other pin types) Reset Source: mod_por_rst_n
  [18] PADCONFIG135_RXACTIVE rw — Input enable for the Pad0 - Receiver disabled1 - Receiver enabled Reset Source: mod_por_rst_n
  [17] PADCONFIG135_PULLTYPESEL rw — Pad Pullup / Pulldown type selection0 - Pulldown selected1 - Pullup selected Reset Source: mod_por_rst_n
  [16] PADCONFIG135_PULLUDEN rw — Pad Pullup / Pulldown enable. This is an active low signal.0 - Pullup / Pulldown enabled1 - Pullup / Pulldown disabled Reset Source: mod_por_rst_n
  [15] PADCONFIG135_FORCE_DS_EN rw — Enable pad Deep Sleep controls by overriding WKUP DM gating0 - Deep Sleep pad controls are gated by the WKUP DM1 - Activate Deep Sleep pad controls (override WKUP DM gating logic) Reset Source: mod_por_rst_n
  [14] PADCONFIG135_ST_EN rw — Receiver Schmitt Trigger enable 0 - Schmitt trigger input disabled 1 - Schmitt trigger input enabled Reset Source: mod_por_rst_n
  [13:11] PADCONFIG135_DEBOUNCE_SEL rw — Selects the debouce period for the pad. Reset Source: mod_por_rst_n
  [8] PADCONFIG135_WK_LVL_POL rw — Level Sensitive Wakeup PolarityThis bit is not relevant unless wk_lvl_en is set to 1'b1.0 - Low. A low (0) value on the pin causes a wakeup1 - High. A high (1) value on the pin causes a wakeup Reset Source: mod_por_rst_n
  [7] PADCONFIG135_WK_LVL_EN rw — Level Sensitive Wakeup Enable0 - Disabled. Wakeup is triggered by change of the pin input value1 - Enabled. Wakeup is triggered when the pin matches the value specified by wk_lvl_pol. The chosen polarity must be maintained. (e.g. until wakeup completion is confirmed) Reset Source: mod_por_rst_n
  [3:0] PADCONFIG135_MUXMODE rw — Pad functional signal mux selectionField values (others are reserved):4'b0000 - Mux Mode 04'b0001 - Mux Mode 14'b0010 - Mux Mode 24'b0011 - Mux Mode 34'b0100 - Mux Mode 44'b0101 - Mux Mode 54'b0110 - Mux Mode 64'b0111 - Mux Mode 74'b1000 - Mux Mode 84'b1001 - Mux Mode 94'b1010 - Mux Mode 104'b1011 - Mux Mode 114'b1100 - Mux Mode 124'b1101 - Mux Mode 134'b1110 - Mux Mode 144'b1111 - Mux Mode 15 Reset Source: mod_por_rst_n
{0x4000+4i} main_padcfg_ctrl_mmr_cfg0_PADCONFIG{i} (i=136..141)
  fields as main_padcfg_ctrl_mmr_cfg0_PADCONFIG0
0x4238 main_padcfg_ctrl_mmr_cfg0_PADCONFIG142 reset 0x8054000
  [31] PADCONFIG142_LOCK rw — Lock 0 - Padconfig register is unlocked 1 - Padconfig register is locked from further writes Reset Source: mod_por_rst_n
  [30] PADCONFIG142_WKUP_EVT ro — Wakeup event status 0 - No wake event on pin 1 - Wake event occurred on pin Reset Source: mod_por_rst_n
  [29] PADCONFIG142_WKUP_EN rw — Wakeup enable 0 - Wakeup operation disabled 1 - Wakeup operation enabled Reset Source: mod_por_rst_n
  [28] PADCONFIG142_DS_PULLTYPE_SEL rw — Deep Sleep pull-up/down selection 0 - Offmode pulldown selected 1 - Offmode pullup selected Reset Source: mod_por_rst_n
  [27] PADCONFIG142_DS_PULLUD_EN rw — Deep Sleep pull-up/down enable (active low) 0 - Pullup / pulldown is enabled 1 - Pullup / pulldown is disabled Reset Source: mod_por_rst_n
  [26] PADCONFIG142_DSOUT_VAL rw — Deep Sleep output value 0 - Output value is 0 1 - Output value is 1 Reset Source: mod_por_rst_n
  [25] PADCONFIG142_DSOUT_DIS rw — Deep Sleep output disable 0 - Output enabled 1 - Output disabled Reset Source: mod_por_rst_n
  [24] PADCONFIG142_DS_EN rw — Deep Sleep override control 0 - IO keeps its previous state when Deep Sleep mode is active 1 - IO state is forced to OFF mode value when Deep Sleep mode is active Reset Source: mod_por_rst_n
  [23] PADCONFIG142_ISO_BYP rw — Isolation Bypass0 - IO isolation is preserved1 - IO isolation is bypassed Reset Source: mod_por_rst_n
  [22] PADCONFIG142_ISO_OVR rw — Isolation Override0 - IO isolation is preserved1 - IO isolation is overridden Reset Source: mod_por_rst_n
  [21] PADCONFIG142_TX_DIS rw — Driver Disable0 - Driver is enabled1 - Driver is disabled Reset Source: mod_por_rst_n
  [20:19] PADCONFIG142_DRV_STR rw — Drive Strength Control . Selects the drive strength value for LVCMOS pins. (Does not apply to other pin types) Reset Source: mod_por_rst_n
  [18] PADCONFIG142_RXACTIVE rw — Input enable for the Pad0 - Receiver disabled1 - Receiver enabled Reset Source: mod_por_rst_n
  [17] PADCONFIG142_PULLTYPESEL rw — Pad Pullup / Pulldown type selection0 - Pulldown selected1 - Pullup selected Reset Source: mod_por_rst_n
  [16] PADCONFIG142_PULLUDEN rw — Pad Pullup / Pulldown enable. This is an active low signal.0 - Pullup / Pulldown enabled1 - Pullup / Pulldown disabled Reset Source: mod_por_rst_n
  [15] PADCONFIG142_FORCE_DS_EN rw — Enable pad Deep Sleep controls by overriding WKUP DM gating0 - Deep Sleep pad controls are gated by the WKUP DM1 - Activate Deep Sleep pad controls (override WKUP DM gating logic) Reset Source: mod_por_rst_n
  [14] PADCONFIG142_ST_EN rw — Receiver Schmitt Trigger enable 0 - Schmitt trigger input disabled 1 - Schmitt trigger input enabled Reset Source: mod_por_rst_n
  [13:11] PADCONFIG142_DEBOUNCE_SEL rw — Selects the debouce period for the pad. Reset Source: mod_por_rst_n
  [8] PADCONFIG142_WK_LVL_POL rw — Level Sensitive Wakeup PolarityThis bit is not relevant unless wk_lvl_en is set to 1'b1.0 - Low. A low (0) value on the pin causes a wakeup1 - High. A high (1) value on the pin causes a wakeup Reset Source: mod_por_rst_n
  [7] PADCONFIG142_WK_LVL_EN rw — Level Sensitive Wakeup Enable0 - Disabled. Wakeup is triggered by change of the pin input value1 - Enabled. Wakeup is triggered when the pin matches the value specified by wk_lvl_pol. The chosen polarity must be maintained. (e.g. until wakeup completion is confirmed) Reset Source: mod_por_rst_n
  [3:0] PADCONFIG142_MUXMODE rw — Pad functional signal mux selectionField values (others are reserved):4'b0000 - Mux Mode 04'b0001 - Mux Mode 14'b0010 - Mux Mode 24'b0011 - Mux Mode 34'b0100 - Mux Mode 44'b0101 - Mux Mode 54'b0110 - Mux Mode 64'b0111 - Mux Mode 74'b1000 - Mux Mode 84'b1001 - Mux Mode 94'b1010 - Mux Mode 104'b1011 - Mux Mode 114'b1100 - Mux Mode 124'b1101 - Mux Mode 134'b1110 - Mux Mode 144'b1111 - Mux Mode 15 Reset Source: mod_por_rst_n
